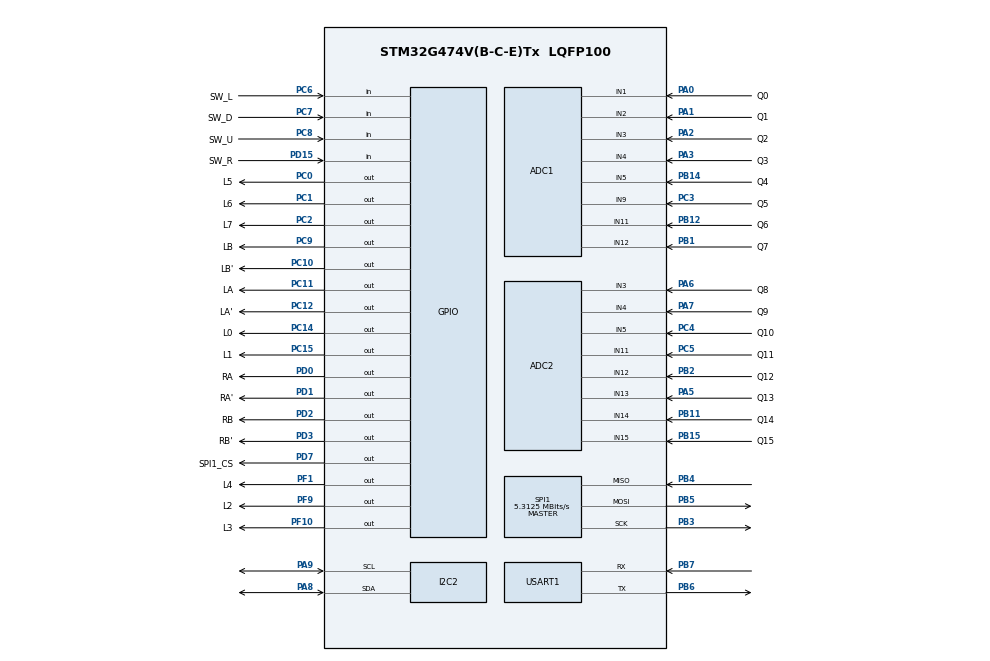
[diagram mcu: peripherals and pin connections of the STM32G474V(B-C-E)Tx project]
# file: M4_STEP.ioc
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ADC1.Channel-0\#ChannelRegularConversion=ADC_CHANNEL_1
ADC1.Channel-1\#ChannelRegularConversion=ADC_CHANNEL_2
ADC1.Channel-2\#ChannelRegularConversion=ADC_CHANNEL_3
ADC1.Channel-3\#ChannelRegularConversion=ADC_CHANNEL_4
ADC1.Channel-4\#ChannelRegularConversion=ADC_CHANNEL_5
ADC1.Channel-5\#ChannelRegularConversion=ADC_CHANNEL_9
ADC1.Channel-6\#ChannelRegularConversion=ADC_CHANNEL_11
ADC1.Channel-7\#ChannelRegularConversion=ADC_CHANNEL_12
ADC1.DMAContinuousRequests=DISABLE
ADC1.DiscontinuousConvMode=ENABLE
ADC1.ExternalTrigConv=ADC_EXTERNALTRIG_T2_TRGO
ADC1.NbrOfConversion=8
ADC1.NbrOfConversionFlag=1
ADC1.OffsetNumber-0\#ChannelRegularConversion=ADC_OFFSET_NONE
ADC1.OffsetNumber-1\#ChannelRegularConversion=ADC_OFFSET_NONE
ADC1.OffsetNumber-2\#ChannelRegularConversion=ADC_OFFSET_NONE
ADC1.OffsetNumber-3\#ChannelRegularConversion=ADC_OFFSET_NONE
ADC1.OffsetNumber-4\#ChannelRegularConversion=ADC_OFFSET_NONE
ADC1.OffsetNumber-5\#ChannelRegularConversion=ADC_OFFSET_NONE
ADC1.OffsetNumber-6\#ChannelRegularConversion=ADC_OFFSET_NONE
ADC1.OffsetNumber-7\#ChannelRegularConversion=ADC_OFFSET_NONE
ADC1.Overrun=ADC_OVR_DATA_OVERWRITTEN
ADC1.Rank-0\#ChannelRegularConversion=1
ADC1.Rank-1\#ChannelRegularConversion=2
ADC1.Rank-2\#ChannelRegularConversion=3
ADC1.Rank-3\#ChannelRegularConversion=4
ADC1.Rank-4\#ChannelRegularConversion=5
ADC1.Rank-5\#ChannelRegularConversion=6
ADC1.Rank-6\#ChannelRegularConversion=7
ADC1.Rank-7\#ChannelRegularConversion=8
ADC1.SamplingTime-0\#ChannelRegularConversion=ADC_SAMPLETIME_6CYCLES_5
ADC1.SamplingTime-1\#ChannelRegularConversion=ADC_SAMPLETIME_6CYCLES_5
ADC1.SamplingTime-2\#ChannelRegularConversion=ADC_SAMPLETIME_6CYCLES_5
ADC1.SamplingTime-3\#ChannelRegularConversion=ADC_SAMPLETIME_6CYCLES_5
ADC1.SamplingTime-4\#ChannelRegularConversion=ADC_SAMPLETIME_6CYCLES_5
ADC1.SamplingTime-5\#ChannelRegularConversion=ADC_SAMPLETIME_6CYCLES_5
ADC1.SamplingTime-6\#ChannelRegularConversion=ADC_SAMPLETIME_6CYCLES_5
ADC1.SamplingTime-7\#ChannelRegularConversion=ADC_SAMPLETIME_6CYCLES_5
ADC1.master=1
ADC2.Channel-0\#ChannelRegularConversion=ADC_CHANNEL_3
ADC2.Channel-1\#ChannelRegularConversion=ADC_CHANNEL_4
ADC2.Channel-2\#ChannelRegularConversion=ADC_CHANNEL_5
ADC2.Channel-3\#ChannelRegularConversion=ADC_CHANNEL_11
ADC2.Channel-4\#ChannelRegularConversion=ADC_CHANNEL_12
ADC2.Channel-5\#ChannelRegularConversion=ADC_CHANNEL_13
ADC2.Channel-6\#ChannelRegularConversion=ADC_CHANNEL_14
ADC2.Channel-7\#ChannelRegularConversion=ADC_CHANNEL_15
ADC2.DMAContinuousRequests=DISABLE
ADC2.DiscontinuousConvMode=ENABLE
ADC2.ExternalTrigConv=ADC_EXTERNALTRIG_T2_TRGO
ADC2.NbrOfConversion=8
ADC2.NbrOfConversionFlag=1
ADC2.OffsetNumber-0\#ChannelRegularConversion=ADC_OFFSET_NONE
ADC2.OffsetNumber-1\#ChannelRegularConversion=ADC_OFFSET_NONE
ADC2.OffsetNumber-2\#ChannelRegularConversion=ADC_OFFSET_NONE
ADC2.OffsetNumber-3\#ChannelRegularConversion=ADC_OFFSET_NONE
ADC2.OffsetNumber-4\#ChannelRegularConversion=ADC_OFFSET_NONE
ADC2.OffsetNumber-5\#ChannelRegularConversion=ADC_OFFSET_NONE
ADC2.OffsetNumber-6\#ChannelRegularConversion=ADC_OFFSET_NONE
ADC2.OffsetNumber-7\#ChannelRegularConversion=ADC_OFFSET_NONE
ADC2.Overrun=ADC_OVR_DATA_OVERWRITTEN
ADC2.Rank-0\#ChannelRegularConversion=1
ADC2.Rank-1\#ChannelRegularConversion=2
ADC2.Rank-2\#ChannelRegularConversion=3
ADC2.Rank-3\#ChannelRegularConversion=4
ADC2.Rank-4\#ChannelRegularConversion=5
ADC2.Rank-5\#ChannelRegularConversion=6
ADC2.Rank-6\#ChannelRegularConversion=7
ADC2.Rank-7\#ChannelRegularConversion=8
ADC2.SamplingTime-0\#ChannelRegularConversion=ADC_SAMPLETIME_6CYCLES_5
ADC2.SamplingTime-1\#ChannelRegularConversion=ADC_SAMPLETIME_6CYCLES_5
ADC2.SamplingTime-2\#ChannelRegularConversion=ADC_SAMPLETIME_6CYCLES_5
ADC2.SamplingTime-3\#ChannelRegularConversion=ADC_SAMPLETIME_6CYCLES_5
ADC2.SamplingTime-4\#ChannelRegularConversion=ADC_SAMPLETIME_6CYCLES_5
ADC2.SamplingTime-5\#ChannelRegularConversion=ADC_SAMPLETIME_6CYCLES_5
ADC2.SamplingTime-6\#ChannelRegularConversion=ADC_SAMPLETIME_6CYCLES_5
ADC2.SamplingTime-7\#ChannelRegularConversion=ADC_SAMPLETIME_6CYCLES_5
I2C2.Timing=0x40B285C2
Mcu.Family=STM32G4
Mcu.Name=STM32G474V(B-C-E)Tx
Mcu.Package=LQFP100
NVIC.ADC1_2_IRQn=true\:0\:0\:true\:false\:true\:true\:true\:true
NVIC.PriorityGroup=NVIC_PRIORITYGROUP_4
NVIC.TIM2_IRQn=true\:1\:0\:true\:false\:true\:true\:true\:true
PA0.GPIO_Label=Q0
PA0.Mode=IN1-Single-Ended
PA0.Signal=ADC1_IN1
PA1.GPIO_Label=Q1
PA1.Mode=IN2-Single-Ended
PA1.Signal=ADC1_IN2
PA13.Mode=Serial_Wire
PA13.Signal=SYS_JTMS-SWDIO
PA14.Mode=Serial_Wire
PA14.Signal=SYS_JTCK-SWCLK
PA2.GPIO_Label=Q2
PA2.Mode=IN3-Single-Ended
PA2.Signal=ADC1_IN3
PA3.GPIO_Label=Q3
PA3.Mode=IN4-Single-Ended
PA3.Signal=ADC1_IN4
PA5.GPIO_Label=Q13
PA5.Mode=IN13-Single-Ended
PA5.Signal=ADC2_IN13
PA6.GPIO_Label=Q8
PA6.Mode=IN3-Single-Ended
PA6.Signal=ADC2_IN3
PA7.GPIO_Label=Q9
PA7.Mode=IN4-Single-Ended
PA7.Signal=ADC2_IN4
PA8.Mode=I2C
PA8.Signal=I2C2_SDA
PA9.Mode=I2C
PA9.Signal=I2C2_SCL
PB1.GPIO_Label=Q7
PB1.Mode=IN12-Single-Ended
PB1.Signal=ADC1_IN12
PB11.GPIO_Label=Q14
PB11.Mode=IN14-Single-Ended
PB11.Signal=ADC2_IN14
PB12.GPIO_Label=Q6
PB12.Mode=IN11-Single-Ended
PB12.Signal=ADC1_IN11
PB14.GPIO_Label=Q4
PB14.Mode=IN5-Single-Ended
PB14.Signal=ADC1_IN5
PB15.GPIO_Label=Q15
PB15.Mode=IN15-Single-Ended
PB15.Signal=ADC2_IN15
PB2.GPIO_Label=Q12
PB2.Mode=IN12-Single-Ended
PB2.Signal=ADC2_IN12
PB3.Mode=Full_Duplex_Master
PB3.Signal=SPI1_SCK
PB4.Mode=Full_Duplex_Master
PB4.Signal=SPI1_MISO
PB5.Mode=Full_Duplex_Master
PB5.Signal=SPI1_MOSI
PB6.Mode=Asynchronous
PB6.Signal=USART1_TX
PB7.Mode=Asynchronous
PB7.Signal=USART1_RX
PC0.GPIO_Label=L5
PC0.GPIO_PuPd=GPIO_PULLDOWN
PC0.GPIO_Speed=GPIO_SPEED_FREQ_LOW
PC0.PinState=GPIO_PIN_RESET
PC0.Signal=GPIO_Output
PC1.GPIO_Label=L6
PC1.GPIO_PuPd=GPIO_PULLDOWN
PC1.GPIO_Speed=GPIO_SPEED_FREQ_LOW
PC1.Signal=GPIO_Output
PC10.GPIO_Label=LB'
PC10.GPIO_PuPd=GPIO_PULLDOWN
PC10.GPIO_Speed=GPIO_SPEED_FREQ_HIGH
PC10.Signal=GPIO_Output
PC11.GPIO_Label=LA
PC11.GPIO_PuPd=GPIO_PULLDOWN
PC11.GPIO_Speed=GPIO_SPEED_FREQ_HIGH
PC11.Signal=GPIO_Output
PC12.GPIO_Label=LA'
PC12.GPIO_PuPd=GPIO_PULLDOWN
PC12.GPIO_Speed=GPIO_SPEED_FREQ_HIGH
PC12.Signal=GPIO_Output
PC14-OSC32_IN.GPIO_Label=L0
PC14-OSC32_IN.GPIO_PuPd=GPIO_PULLDOWN
PC14-OSC32_IN.Signal=GPIO_Output
PC15-OSC32_OUT.GPIO_Label=L1
PC15-OSC32_OUT.GPIO_PuPd=GPIO_PULLDOWN
PC15-OSC32_OUT.Signal=GPIO_Output
PC2.GPIO_Label=L7
PC2.GPIO_PuPd=GPIO_PULLDOWN
PC2.GPIO_Speed=GPIO_SPEED_FREQ_LOW
PC2.Signal=GPIO_Output
PC3.GPIO_Label=Q5
PC3.Mode=IN9-Single-Ended
PC3.Signal=ADC1_IN9
PC4.GPIO_Label=Q10
PC4.Mode=IN5-Single-Ended
PC4.Signal=ADC2_IN5
PC5.GPIO_Label=Q11
PC5.Mode=IN11-Single-Ended
PC5.Signal=ADC2_IN11
PC6.GPIO_Label=SW_L
PC6.GPIO_PuPd=GPIO_PULLUP
PC6.Signal=GPIO_Input
PC7.GPIO_Label=SW_D
PC7.GPIO_PuPd=GPIO_PULLUP
PC7.Signal=GPIO_Input
PC8.GPIO_Label=SW_U
PC8.GPIO_PuPd=GPIO_PULLUP
PC8.Signal=GPIO_Input
PC9.GPIO_Label=LB
PC9.GPIO_PuPd=GPIO_PULLDOWN
PC9.GPIO_Speed=GPIO_SPEED_FREQ_HIGH
PC9.Signal=GPIO_Output
PD0.GPIO_Label=RA
PD0.GPIO_PuPd=GPIO_PULLDOWN
PD0.GPIO_Speed=GPIO_SPEED_FREQ_HIGH
PD0.Signal=GPIO_Output
PD1.GPIO_Label=RA'
PD1.GPIO_PuPd=GPIO_PULLDOWN
PD1.GPIO_Speed=GPIO_SPEED_FREQ_HIGH
PD1.Signal=GPIO_Output
PD15.GPIO_Label=SW_R
PD15.GPIO_PuPd=GPIO_PULLUP
PD15.Signal=GPIO_Input
PD2.GPIO_Label=RB
PD2.GPIO_PuPd=GPIO_PULLDOWN
PD2.GPIO_Speed=GPIO_SPEED_FREQ_HIGH
PD2.Signal=GPIO_Output
PD3.GPIO_Label=RB'
PD3.GPIO_PuPd=GPIO_PULLDOWN
PD3.GPIO_Speed=GPIO_SPEED_FREQ_HIGH
PD3.Signal=GPIO_Output
PD7.GPIO_Label=SPI1_CS
PD7.Signal=GPIO_Output
PF0-OSC_IN.Mode=HSE-External-Clock-Source
PF0-OSC_IN.Signal=RCC_OSC_IN
PF1-OSC_OUT.GPIO_Label=L4
PF1-OSC_OUT.GPIO_PuPd=GPIO_PULLDOWN
PF1-OSC_OUT.Signal=GPIO_Output
PF10.GPIO_Label=L3
PF10.GPIO_PuPd=GPIO_PULLDOWN
PF10.Signal=GPIO_Output
PF9.GPIO_Label=L2
PF9.GPIO_PuPd=GPIO_PULLDOWN
PF9.Signal=GPIO_Output
ProjectManager.HeapSize=0x200
ProjectManager.StackSize=0x400
ProjectManager.TargetToolchain=CMake
RCC.ADC12Freq_Value=170000000
RCC.ADC345Freq_Value=170000000
RCC.AHBFreq_Value=170000000
RCC.APB1Freq_Value=170000000
RCC.APB1TimFreq_Value=170000000
RCC.APB2Freq_Value=170000000
RCC.APB2TimFreq_Value=170000000
RCC.CortexFreq_Value=170000000
RCC.EXTERNAL_CLOCK_VALUE=12288000
RCC.HCLKFreq_Value=170000000
RCC.HSE_VALUE=20000000
RCC.HSI48_VALUE=48000000
RCC.HSI_VALUE=16000000
RCC.LSE_VALUE=32768
RCC.PLLM=RCC_PLLM_DIV2
RCC.PLLN=34
RCC.PLLSourceVirtual=RCC_PLLSOURCE_HSE
RCC.SYSCLKFreq_VALUE=170000000
RCC.SYSCLKSource=RCC_SYSCLKSOURCE_PLLCLK
RCC.USBFreq_Value=170000000
RCC.VCOOutputFreq_Value=340000000
SPI1.BaudRatePrescaler=SPI_BAUDRATEPRESCALER_32
SPI1.CalculateBaudRate=5.3125 MBits/s
SPI1.DataSize=SPI_DATASIZE_8BIT
SPI1.Direction=SPI_DIRECTION_2LINES
SPI1.Mode=SPI_MODE_MASTER
SPI1.VirtualType=VM_MASTER
TIM2.Channel-PWM\ Generation2\ No\ Output=TIM_CHANNEL_2
TIM2.OCMode_PWM-PWM\ Generation2\ No\ Output=TIM_OCMODE_PWM2
TIM2.PeriodNoDither=49
TIM2.Prescaler=84
TIM2.PulseNoDither_2=25
TIM2.TIM_MasterOutputTrigger=TIM_TRGO_OC2REF
USART1.SwapParam=ADVFEATURE_SWAP_DISABLE
USART1.VirtualMode-Asynchronous=VM_ASYNC
VP_SYS_VS_DBSignals.Mode=DisableDeadBatterySignals
VP_TIM2_VS_ClockSourceINT.Mode=Internal
VP_TIM2_VS_no_output2.Mode=PWM Generation2 No Output
board=custom

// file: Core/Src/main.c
/* USER CODE BEGIN Header */
/**
  ******************************************************************************
  * @file           : main.c
  * @brief          : Main program body
  ******************************************************************************
  * @attention
  *
  * Copyright (c) 2026 STMicroelectronics.
  * All rights reserved.
  *
  * This software is licensed under terms that can be found in the LICENSE file
  * in the root directory of this software component.
  * If no LICENSE file comes with this software, it is provided AS-IS.
  *
  ******************************************************************************
  */
/* USER CODE END Header */
#include "main.h"
#include "adc.h"
#include "i2c.h"
#include "spi.h"
#include "tim.h"
#include "usart.h"
#include "gpio.h"

/* USER CODE BEGIN Includes */
#include "menu.h"
#include "sensor.h"
#include "search.h"
#include "rom.h"
#include "variable.h"
#include <string.h>
#include <stdio.h>
/* USER CODE END Includes */

void SystemClock_Config(void);

int main(void)
{

  /* MCU Configuration--------------------------------------------------------*/

  /* Reset of all peripherals, Initializes the Flash interface and the Systick. */
  LL_APB2_GRP1_EnableClock(LL_APB2_GRP1_PERIPH_SYSCFG);
  LL_APB1_GRP1_EnableClock(LL_APB1_GRP1_PERIPH_PWR);

  /* System interrupt init*/
  NVIC_SetPriorityGrouping(NVIC_PRIORITYGROUP_4);

  /* SysTick_IRQn interrupt configuration */
  NVIC_SetPriority(SysTick_IRQn, NVIC_EncodePriority(NVIC_GetPriorityGrouping(),3, 0));

  /** Disable the internal Pull-Up in Dead Battery pins of UCPD peripheral
  */
  LL_PWR_DisableUCPDDeadBattery();

  /* Configure the system clock */
  SystemClock_Config();

  /* Initialize all configured peripherals */
  MX_GPIO_Init();
  MX_ADC1_Init();
  MX_ADC2_Init();
  MX_I2C2_Init();
  MX_SPI1_Init();
  MX_USART1_UART_Init();
  MX_TIM2_Init();
  /* USER CODE BEGIN 2 */
  Variable_Init();
  sen_vari_init();
  Race_Init();
  //Rom_ReadAll();
  printf("Hello USART1\r\n");
  menu_start();

  /* USER CODE END 2 */

  /* Infinite loop */
  while (1)
  {

  }
}

void SystemClock_Config(void)
{
  LL_FLASH_SetLatency(LL_FLASH_LATENCY_4);
  while(LL_FLASH_GetLatency() != LL_FLASH_LATENCY_4)
  {
  }
  LL_PWR_EnableRange1BoostMode();
  LL_RCC_HSE_EnableBypass();
  LL_RCC_HSE_Enable();
   /* Wait till HSE is ready */
  while(LL_RCC_HSE_IsReady() != 1)
  {
  }

  LL_RCC_PLL_ConfigDomain_SYS(LL_RCC_PLLSOURCE_HSE, LL_RCC_PLLM_DIV_2, 34, LL_RCC_PLLR_DIV_2);
  LL_RCC_PLL_EnableDomain_SYS();
  LL_RCC_PLL_Enable();
   /* Wait till PLL is ready */
  while(LL_RCC_PLL_IsReady() != 1)
  {
  }

  LL_RCC_SetSysClkSource(LL_RCC_SYS_CLKSOURCE_PLL);
  LL_RCC_SetAHBPrescaler(LL_RCC_SYSCLK_DIV_2);
   /* Wait till System clock is ready */
  while(LL_RCC_GetSysClkSource() != LL_RCC_SYS_CLKSOURCE_STATUS_PLL)
  {
  }

  /* Insure 1us transition state at intermediate medium speed clock*/
  for (__IO uint32_t i = (170 >> 1); i !=0; i--);

  /* Set AHB prescaler*/
  LL_RCC_SetAHBPrescaler(LL_RCC_SYSCLK_DIV_1);
  LL_RCC_SetAPB1Prescaler(LL_RCC_APB1_DIV_1);
  LL_RCC_SetAPB2Prescaler(LL_RCC_APB2_DIV_1);

  LL_Init1msTick(170000000);

  LL_SetSystemCoreClock(170000000);
}

void Error_Handler(void)
{
  __disable_irq();
  while (1)
  {
  }
}
